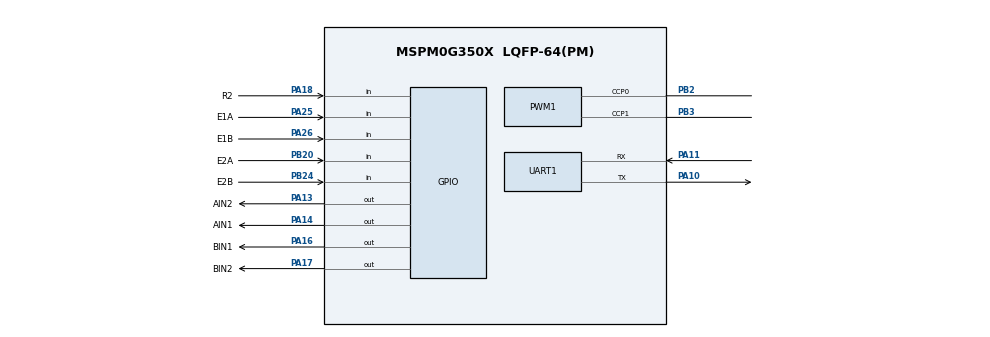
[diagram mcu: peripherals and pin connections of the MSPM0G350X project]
/**
 * @cliArgs --device "MSPM0G350X" --part "Default" --package "LQFP-64(PM)" --product "mspm0_sdk@2.05.01.01"
 * @versions {"tool":"1.24.1+4189"}
 */

/**
 * Import the modules used in this configuration.
 */
const GPIO    = scripting.addModule("/ti/driverlib/GPIO", {}, false);
const GPIO1   = GPIO.addInstance();
const GPIO2   = GPIO.addInstance();
const GPIO3   = GPIO.addInstance();
const GPIO4   = GPIO.addInstance();
const GPIO5   = GPIO.addInstance();
const GPIO6   = GPIO.addInstance();
const GPIO7   = GPIO.addInstance();
const GPIO8   = GPIO.addInstance();
const GPIO9   = GPIO.addInstance();
const I2C     = scripting.addModule("/ti/driverlib/I2C", {}, false);
const I2C1    = I2C.addInstance();
const PWM     = scripting.addModule("/ti/driverlib/PWM", {}, false);
const PWM1    = PWM.addInstance();
const SYSCTL  = scripting.addModule("/ti/driverlib/SYSCTL");
const SYSTICK = scripting.addModule("/ti/driverlib/SYSTICK");
const TIMER   = scripting.addModule("/ti/driverlib/TIMER", {}, false);
const TIMER1  = TIMER.addInstance();
const UART    = scripting.addModule("/ti/driverlib/UART", {}, false);
const UART1   = UART.addInstance();

/**
 * Write custom configuration values to the imported modules.
 */
const divider7       = system.clockTree["PLL_PDIV"];
divider7.divideValue = 2;

const divider9       = system.clockTree["UDIV"];
divider9.divideValue = 2;

const gate7  = system.clockTree["MFCLKGATE"];
gate7.enable = true;

const multiplier2         = system.clockTree["PLL_QDIV"];
multiplier2.multiplyValue = 5;

const mux8       = system.clockTree["HSCLKMUX"];
mux8.inputSelect = "HSCLKMUX_SYSPLL2X";

GPIO1.$name                              = "KEY_KEY1";
GPIO1.associatedPins[0].direction        = "INPUT";
GPIO1.associatedPins[0].$name            = "KEY1";
GPIO1.associatedPins[0].assignedPort     = "PORTB";
GPIO1.associatedPins[0].assignedPin      = "8";
GPIO1.associatedPins[0].internalResistor = "PULL_UP";

const Board = scripting.addModule("/ti/driverlib/Board", {}, false);

GPIO2.$name                          = "LED";
GPIO2.associatedPins[0].$name        = "led";
GPIO2.associatedPins[0].assignedPort = "PORTB";
GPIO2.associatedPins[0].assignedPin  = "14";

GPIO3.port                          = "PORTA";
GPIO3.$name                         = "BIN";
GPIO3.associatedPins.create(2);
GPIO3.associatedPins[0].$name       = "BIN1";
GPIO3.associatedPins[0].pin.$assign = "PA16";
GPIO3.associatedPins[1].$name       = "BIN2";
GPIO3.associatedPins[1].pin.$assign = "PA17";

GPIO4.port                          = "PORTA";
GPIO4.$name                         = "AIN";
GPIO4.associatedPins.create(2);
GPIO4.associatedPins[0].$name       = "AIN1";
GPIO4.associatedPins[0].pin.$assign = "PA14";
GPIO4.associatedPins[1].$name       = "AIN2";
GPIO4.associatedPins[1].pin.$assign = "PA13";

GPIO5.$name                               = "ENCODERA";
GPIO5.associatedPins.create(2);
GPIO5.associatedPins[0].$name             = "E1A";
GPIO5.associatedPins[0].direction         = "INPUT";
GPIO5.associatedPins[0].polarity          = "RISE";
GPIO5.associatedPins[0].interruptPriority = "0";
GPIO5.associatedPins[0].interruptEn       = true;
GPIO5.associatedPins[0].pin.$assign       = "PA25";
GPIO5.associatedPins[1].$name             = "E1B";
GPIO5.associatedPins[1].direction         = "INPUT";
GPIO5.associatedPins[1].polarity          = "RISE";
GPIO5.associatedPins[1].interruptPriority = "0";
GPIO5.associatedPins[1].interruptEn       = true;
GPIO5.associatedPins[1].pin.$assign       = "PA26";

GPIO6.$name                               = "ENCODERB";
GPIO6.associatedPins.create(2);
GPIO6.associatedPins[0].$name             = "E2A";
GPIO6.associatedPins[0].direction         = "INPUT";
GPIO6.associatedPins[0].polarity          = "RISE";
GPIO6.associatedPins[0].interruptPriority = "0";
GPIO6.associatedPins[0].interruptEn       = true;
GPIO6.associatedPins[0].pin.$assign       = "PB20";
GPIO6.associatedPins[1].$name             = "E2B";
GPIO6.associatedPins[1].direction         = "INPUT";
GPIO6.associatedPins[1].polarity          = "RISE";
GPIO6.associatedPins[1].interruptPriority = "0";
GPIO6.associatedPins[1].interruptEn       = true;
GPIO6.associatedPins[1].pin.$assign       = "PB24";

GPIO7.$name                          = "SENSOR";
GPIO7.associatedPins.create(5);
GPIO7.associatedPins[0].direction    = "INPUT";
GPIO7.associatedPins[0].$name        = "L2";
GPIO7.associatedPins[0].assignedPort = "PORTA";
GPIO7.associatedPins[0].assignedPin  = "21";
GPIO7.associatedPins[1].$name        = "L1";
GPIO7.associatedPins[1].direction    = "INPUT";
GPIO7.associatedPins[1].assignedPort = "PORTB";
GPIO7.associatedPins[1].assignedPin  = "19";
GPIO7.associatedPins[2].$name        = "M";
GPIO7.associatedPins[2].direction    = "INPUT";
GPIO7.associatedPins[2].assignedPin  = "18";
GPIO7.associatedPins[2].assignedPort = "PORTB";
GPIO7.associatedPins[3].$name        = "R1";
GPIO7.associatedPins[3].direction    = "INPUT";
GPIO7.associatedPins[3].assignedPort = "PORTB";
GPIO7.associatedPins[3].assignedPin  = "17";
GPIO7.associatedPins[4].$name        = "R2";
GPIO7.associatedPins[4].direction    = "INPUT";
GPIO7.associatedPins[4].assignedPort = "PORTA";
GPIO7.associatedPins[4].assignedPin  = "18";
GPIO7.associatedPins[4].pin.$assign  = "PA18";

GPIO8.$name                   = "OLED";
GPIO8.associatedPins.create(3);
GPIO8.associatedPins[0].$name = "RES";
GPIO8.associatedPins[1].$name = "DC";
GPIO8.associatedPins[2].$name = "CS";

GPIO9.$name                              = "KEY_KEY2";
GPIO9.associatedPins[0].$name            = "KEY2";
GPIO9.associatedPins[0].direction        = "INPUT";
GPIO9.associatedPins[0].internalResistor = "PULL_UP";

I2C1.basicEnableController             = true;
I2C1.basicClockSourceDivider           = 4;
I2C1.basicControllerBusSpeed           = 500000;
I2C1.$name                             = "I2C_OLED";
I2C1.sdaPinConfig.$name                = "ti_driverlib_gpio_GPIOPinGeneric0";
I2C1.sdaPinConfig.hideOutputInversion  = scripting.forceWrite(false);
I2C1.sdaPinConfig.onlyInternalResistor = scripting.forceWrite(false);
I2C1.sdaPinConfig.passedPeripheralType = scripting.forceWrite("Digital");
I2C1.sclPinConfig.$name                = "ti_driverlib_gpio_GPIOPinGeneric1";
I2C1.sclPinConfig.hideOutputInversion  = scripting.forceWrite(false);
I2C1.sclPinConfig.onlyInternalResistor = scripting.forceWrite(false);
I2C1.sclPinConfig.passedPeripheralType = scripting.forceWrite("Digital");

PWM1.$name                      = "PWM_0";
PWM1.timerStartTimer            = true;
PWM1.pwmMode                    = "EDGE_ALIGN_UP";
PWM1.timerCount                 = 8000;
PWM1.peripheral.$assign         = "TIMA1";
PWM1.peripheral.ccp0Pin.$assign = "PB2";
PWM1.peripheral.ccp1Pin.$assign = "PB3";
PWM1.PWM_CHANNEL_0.$name        = "ti_driverlib_pwm_PWMTimerCC0";
PWM1.PWM_CHANNEL_1.$name        = "ti_driverlib_pwm_PWMTimerCC1";
PWM1.ccp0PinConfig.$name        = "ti_driverlib_gpio_GPIOPinGeneric4";
PWM1.ccp1PinConfig.$name        = "ti_driverlib_gpio_GPIOPinGeneric5";

SYSCTL.forceDefaultClkConfig = true;
SYSCTL.clockTreeEn           = true;

SYSTICK.periodEnable  = true;
SYSTICK.systickEnable = true;
SYSTICK.period        = 16777216;

TIMER1.$name              = "TIMER_0";
TIMER1.timerClkPrescale   = 32;
TIMER1.timerMode          = "PERIODIC";
TIMER1.timerStartTimer    = true;
TIMER1.interrupts         = ["ZERO"];
TIMER1.timerPeriod        = "10 ms";
TIMER1.peripheral.$assign = "TIMG0";

UART1.$name                    = "UART_0";
UART1.profile                  = "CONFIG_PROFILE_1";
UART1.peripheral.rxPin.$assign = "PA11";
UART1.peripheral.txPin.$assign = "PA10";
UART1.txPinConfig.$name        = "ti_driverlib_gpio_GPIOPinGeneric2";
UART1.rxPinConfig.$name        = "ti_driverlib_gpio_GPIOPinGeneric3";

/**
 * Pinmux solution for unlocked pins/peripherals. This ensures that minor changes to the automatic solver in a future
 * version of the tool will not impact the pinmux you originally saw.  These lines can be completely deleted in order to
 * re-solve from scratch.
 */
GPIO1.associatedPins[0].pin.$suggestSolution = "PB8";
Board.peripheral.$suggestSolution            = "DEBUGSS";
Board.peripheral.swclkPin.$suggestSolution   = "PA20";
Board.peripheral.swdioPin.$suggestSolution   = "PA19";
GPIO2.associatedPins[0].pin.$suggestSolution = "PB14";
GPIO7.associatedPins[0].pin.$suggestSolution = "PA21";
GPIO7.associatedPins[1].pin.$suggestSolution = "PB19";
GPIO7.associatedPins[2].pin.$suggestSolution = "PB18";
GPIO7.associatedPins[3].pin.$suggestSolution = "PB17";
GPIO8.associatedPins[0].pin.$suggestSolution = "PB15";
GPIO8.associatedPins[1].pin.$suggestSolution = "PB16";
GPIO8.associatedPins[2].pin.$suggestSolution = "PA12";
GPIO9.associatedPins[0].pin.$suggestSolution = "PB13";
I2C1.peripheral.$suggestSolution             = "I2C0";
I2C1.peripheral.sdaPin.$suggestSolution      = "PA0";
I2C1.peripheral.sclPin.$suggestSolution      = "PA1";
UART1.peripheral.$suggestSolution            = "UART0";
